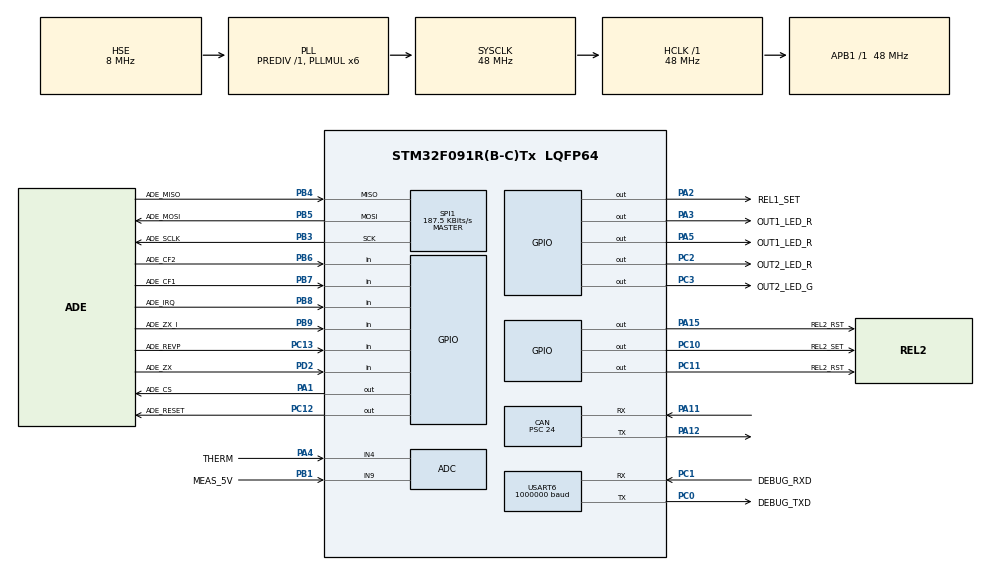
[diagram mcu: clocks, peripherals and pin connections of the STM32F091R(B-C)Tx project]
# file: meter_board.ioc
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CAN.BS1=CAN_BS1_13TQ
CAN.BS2=CAN_BS2_6TQ
CAN.CalculateTimeQuantum=500.0
CAN.Mode=CAN_MODE_LOOPBACK
CAN.Prescaler=24
FREERTOS.Tasks01=defaultTask,0,128,StartDefaultTask,Default,NULL
Mcu.Family=STM32F0
Mcu.Name=STM32F091R(B-C)Tx
Mcu.Package=LQFP64
NVIC.TIM1_BRK_UP_TRG_COM_IRQn=true\:0\:0\:false\:false\:true\:false\:false
NVIC.TimeBase=TIM1_BRK_UP_TRG_COM_IRQn
NVIC.TimeBaseIP=TIM1
PA1.GPIO_Label=ADE_CS
PA1.PinState=GPIO_PIN_SET
PA1.Signal=GPIO_Output
PA11.Mode=Master
PA11.Signal=CAN_RX
PA12.Mode=Master
PA12.Signal=CAN_TX
PA13.Mode=Serial_Wire
PA13.Signal=SYS_SWDIO
PA14.Mode=Serial_Wire
PA14.Signal=SYS_SWCLK
PA15.GPIO_Label=REL2_RST
PA15.Signal=GPIO_Output
PA2.GPIO_Label=REL1_SET
PA2.Signal=GPIO_Output
PA3.GPIO_Label=OUT1_LED_R
PA3.Signal=GPIO_Output
PA4.GPIO_Label=THERM
PA4.Mode=IN4
PA4.Signal=ADC_IN4
PA5.GPIO_Label=OUT1_LED_R
PA5.Signal=GPIO_Output
PB1.GPIO_Label=MEAS_5V
PB1.Mode=IN9
PB1.Signal=ADC_IN9
PB3.GPIO_Label=ADE_SCLK
PB3.Mode=Full_Duplex_Master
PB3.Signal=SPI1_SCK
PB4.GPIO_Label=ADE_MISO
PB4.Mode=Full_Duplex_Master
PB4.Signal=SPI1_MISO
PB5.GPIO_Label=ADE_MOSI
PB5.Mode=Full_Duplex_Master
PB5.Signal=SPI1_MOSI
PB6.GPIO_Label=ADE_CF2
PB6.Signal=GPIO_Input
PB7.GPIO_Label=ADE_CF1
PB7.Signal=GPIO_Input
PB8.GPIO_Label=ADE_IRQ
PB8.Signal=GPIO_Input
PB9.GPIO_Label=ADE_ZX_I
PB9.Signal=GPIO_Input
PC0.GPIO_Label=DEBUG_TXD
PC0.Mode=Asynchronous
PC0.Signal=USART6_TX
PC1.GPIO_Label=DEBUG_RXD
PC1.Mode=Asynchronous
PC1.Signal=USART6_RX
PC10.GPIO_Label=REL2_SET
PC10.Signal=GPIO_Output
PC11.GPIO_Label=REL2_RST
PC11.Signal=GPIO_Output
PC12.GPIO_Label=ADE_RESET
PC12.PinState=GPIO_PIN_SET
PC12.Signal=GPIO_Output
PC13.GPIO_Label=ADE_REVP
PC13.Signal=GPIO_Input
PC14OSC32_IN.GPIO_Label=CAN_LED_G
PC14OSC32_IN.Signal=GPIO_Output
PC15OSC32_OUT.GPIO_Label=CAN_LED_R
PC15OSC32_OUT.Signal=GPIO_Output
PC2.GPIO_Label=OUT2_LED_R
PC2.Signal=GPIO_Output
PC3.GPIO_Label=OUT2_LED_G
PC3.Signal=GPIO_Output
PD2.GPIO_Label=ADE_ZX
PD2.Signal=GPIO_Input
PF0-OSC_IN.Mode=HSE-External-Oscillator
PF0-OSC_IN.Signal=RCC_OSC_IN
PF1-OSC_OUT.Mode=HSE-External-Oscillator
PF1-OSC_OUT.Signal=RCC_OSC_OUT
ProjectManager.HeapSize=0x200
ProjectManager.StackSize=0x400
ProjectManager.TargetToolchain=SW4STM32
RCC.AHBFreq_Value=48000000
RCC.APB1Freq_Value=48000000
RCC.APB1TimFreq_Value=48000000
RCC.HCLKFreq_Value=48000000
RCC.PLLMUL=RCC_PLL_MUL6
RCC.PLLSourceVirtual=RCC_PLLSOURCE_HSE
RCC.SYSCLKFreq_VALUE=48000000
RCC.SYSCLKSource=RCC_SYSCLKSOURCE_PLLCLK
SPI1.BaudRatePrescaler=SPI_BAUDRATEPRESCALER_256
SPI1.CLKPhase=SPI_PHASE_2EDGE
SPI1.CLKPolarity=SPI_POLARITY_HIGH
SPI1.CalculateBaudRate=187.5 KBits/s
SPI1.DataSize=SPI_DATASIZE_8BIT
SPI1.Direction=SPI_DIRECTION_2LINES
SPI1.Mode=SPI_MODE_MASTER
SPI1.VirtualType=VM_MASTER
USART6.BaudRate=1000000
USART6.VirtualMode=VM_ASYNC
USART6.WordLength=WORDLENGTH_8B
VP_FREERTOS_VS_ENABLE.Mode=Enabled
VP_SYS_VS_tim1.Mode=TIM1
board=meter_board

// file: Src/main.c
/**
  ******************************************************************************
  * @file           : main.c
  * @brief          : Main program body
  ******************************************************************************
  * This notice applies to any and all portions of this file
  * that are not between comment pairs USER CODE BEGIN and
  * USER CODE END. Other portions of this file, whether
  * inserted by the user or by software development tools
  * are owned by their respective copyright owners.
  *
  * Copyright (c) 2018 STMicroelectronics International N.V.
  * All rights reserved.
  *
  * Redistribution and use in source and binary forms, with or without
  * modification, are permitted, provided that the following conditions are met:
  *
  * 1. Redistribution of source code must retain the above copyright notice,
  *    this list of conditions and the following disclaimer.
  * 2. Redistributions in binary form must reproduce the above copyright notice,
  *    this list of conditions and the following disclaimer in the documentation
  *    and/or other materials provided with the distribution.
  * 3. Neither the name of STMicroelectronics nor the names of other
  *    contributors to this software may be used to endorse or promote products
  *    derived from this software without specific written permission.
  * 4. This software, including modifications and/or derivative works of this
  *    software, must execute solely and exclusively on microcontroller or
  *    microprocessor devices manufactured by or for STMicroelectronics.
  * 5. Redistribution and use of this software other than as permitted under
  *    this license is void and will automatically terminate your rights under
  *    this license.
  *
  * THIS SOFTWARE IS PROVIDED BY STMICROELECTRONICS AND CONTRIBUTORS "AS IS"
  * AND ANY EXPRESS, IMPLIED OR STATUTORY WARRANTIES, INCLUDING, BUT NOT
  * LIMITED TO, THE IMPLIED WARRANTIES OF MERCHANTABILITY, FITNESS FOR A
  * PARTICULAR PURPOSE AND NON-INFRINGEMENT OF THIRD PARTY INTELLECTUAL PROPERTY
  * RIGHTS ARE DISCLAIMED TO THE FULLEST EXTENT PERMITTED BY LAW. IN NO EVENT
  * SHALL STMICROELECTRONICS OR CONTRIBUTORS BE LIABLE FOR ANY DIRECT, INDIRECT,
  * INCIDENTAL, SPECIAL, EXEMPLARY, OR CONSEQUENTIAL DAMAGES (INCLUDING, BUT NOT
  * LIMITED TO, PROCUREMENT OF SUBSTITUTE GOODS OR SERVICES; LOSS OF USE, DATA,
  * OR PROFITS; OR BUSINESS INTERRUPTION) HOWEVER CAUSED AND ON ANY THEORY OF
  * LIABILITY, WHETHER IN CONTRACT, STRICT LIABILITY, OR TORT (INCLUDING
  * NEGLIGENCE OR OTHERWISE) ARISING IN ANY WAY OUT OF THE USE OF THIS SOFTWARE,
  * EVEN IF ADVISED OF THE POSSIBILITY OF SUCH DAMAGE.
  *
  ******************************************************************************
  */
#include "main.h"
#include "stm32f0xx_hal.h"
#include "cmsis_os.h"
#include "adc.h"
#include "can.h"
#include "spi.h"
#include "usart.h"
#include "gpio.h"

/* USER CODE BEGIN PV */
/* Private variables ---------------------------------------------------------*/

/* USER CODE END PV */

void SystemClock_Config(void);
void MX_FREERTOS_Init(void);

/* USER CODE BEGIN PFP */
/* Private function prototypes -----------------------------------------------*/

/* USER CODE END PFP */

int main(void)
{

  /* MCU Configuration----------------------------------------------------------*/

  /* Reset of all peripherals, Initializes the Flash interface and the Systick. */
  HAL_Init();

  /* Configure the system clock */
  SystemClock_Config();

  /* Initialize all configured peripherals */
  MX_GPIO_Init();
  MX_USART6_UART_Init();
  MX_ADC_Init();
  MX_SPI1_Init();
  MX_CAN_Init();
  /* USER CODE BEGIN 2 */
  __HAL_DBGMCU_FREEZE_TIM1();

  /* USER CODE END 2 */

  /* Call init function for freertos objects (in freertos.c) */
  MX_FREERTOS_Init();

  /* Start scheduler */
  osKernelStart();

  /* We should never get here as control is now taken by the scheduler */

  /* Infinite loop */
	while (1) {

	}

}

void SystemClock_Config(void)
{

  RCC_OscInitTypeDef RCC_OscInitStruct;
  RCC_ClkInitTypeDef RCC_ClkInitStruct;

    /**Initializes the CPU, AHB and APB busses clocks
    */
  RCC_OscInitStruct.OscillatorType = RCC_OSCILLATORTYPE_HSI14|RCC_OSCILLATORTYPE_HSE;
  RCC_OscInitStruct.HSEState = RCC_HSE_ON;
  RCC_OscInitStruct.HSI14State = RCC_HSI14_ON;
  RCC_OscInitStruct.HSI14CalibrationValue = 16;
  RCC_OscInitStruct.PLL.PLLState = RCC_PLL_ON;
  RCC_OscInitStruct.PLL.PLLSource = RCC_PLLSOURCE_HSE;
  RCC_OscInitStruct.PLL.PLLMUL = RCC_PLL_MUL6;
  RCC_OscInitStruct.PLL.PREDIV = RCC_PREDIV_DIV1;
  if (HAL_RCC_OscConfig(&RCC_OscInitStruct) != HAL_OK)
  {
    _Error_Handler(__FILE__, __LINE__);
  }

    /**Initializes the CPU, AHB and APB busses clocks
    */
  RCC_ClkInitStruct.ClockType = RCC_CLOCKTYPE_HCLK|RCC_CLOCKTYPE_SYSCLK
                              |RCC_CLOCKTYPE_PCLK1;
  RCC_ClkInitStruct.SYSCLKSource = RCC_SYSCLKSOURCE_PLLCLK;
  RCC_ClkInitStruct.AHBCLKDivider = RCC_SYSCLK_DIV1;
  RCC_ClkInitStruct.APB1CLKDivider = RCC_HCLK_DIV1;

  if (HAL_RCC_ClockConfig(&RCC_ClkInitStruct, FLASH_LATENCY_1) != HAL_OK)
  {
    _Error_Handler(__FILE__, __LINE__);
  }

    /**Configure the Systick interrupt time
    */
  HAL_SYSTICK_Config(HAL_RCC_GetHCLKFreq()/1000);

    /**Configure the Systick
    */
  HAL_SYSTICK_CLKSourceConfig(SYSTICK_CLKSOURCE_HCLK);

  /* SysTick_IRQn interrupt configuration */
  HAL_NVIC_SetPriority(SysTick_IRQn, 3, 0);
}

void HAL_TIM_PeriodElapsedCallback(TIM_HandleTypeDef *htim)
{
  if (htim->Instance == TIM1) {
    HAL_IncTick();
  }
}

void _Error_Handler(char *file, int line)
{
	while (1) {
	}
}

/************************ (C) COPYRIGHT STMicroelectronics *****END OF FILE****/

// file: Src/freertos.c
/**
 ******************************************************************************
 * File Name          : freertos.c
 * Description        : Code for freertos applications
 ******************************************************************************
 * This notice applies to any and all portions of this file
 * that are not between comment pairs USER CODE BEGIN and
 * USER CODE END. Other portions of this file, whether
 * inserted by the user or by software development tools
 * are owned by their respective copyright owners.
 *
 * Copyright (c) 2018 STMicroelectronics International N.V.
 * All rights reserved.
 *
 * Redistribution and use in source and binary forms, with or without
 * modification, are permitted, provided that the following conditions are met:
 *
 * 1. Redistribution of source code must retain the above copyright notice,
 *    this list of conditions and the following disclaimer.
 * 2. Redistributions in binary form must reproduce the above copyright notice,
 *    this list of conditions and the following disclaimer in the documentation
 *    and/or other materials provided with the distribution.
 * 3. Neither the name of STMicroelectronics nor the names of other
 *    contributors to this software may be used to endorse or promote products
 *    derived from this software without specific written permission.
 * 4. This software, including modifications and/or derivative works of this
 *    software, must execute solely and exclusively on microcontroller or
 *    microprocessor devices manufactured by or for STMicroelectronics.
 * 5. Redistribution and use of this software other than as permitted under
 *    this license is void and will automatically terminate your rights under
 *    this license.
 *
 * THIS SOFTWARE IS PROVIDED BY STMICROELECTRONICS AND CONTRIBUTORS "AS IS"
 * AND ANY EXPRESS, IMPLIED OR STATUTORY WARRANTIES, INCLUDING, BUT NOT
 * LIMITED TO, THE IMPLIED WARRANTIES OF MERCHANTABILITY, FITNESS FOR A
 * PARTICULAR PURPOSE AND NON-INFRINGEMENT OF THIRD PARTY INTELLECTUAL PROPERTY
 * RIGHTS ARE DISCLAIMED TO THE FULLEST EXTENT PERMITTED BY LAW. IN NO EVENT
 * SHALL STMICROELECTRONICS OR CONTRIBUTORS BE LIABLE FOR ANY DIRECT, INDIRECT,
 * INCIDENTAL, SPECIAL, EXEMPLARY, OR CONSEQUENTIAL DAMAGES (INCLUDING, BUT NOT
 * LIMITED TO, PROCUREMENT OF SUBSTITUTE GOODS OR SERVICES; LOSS OF USE, DATA,
 * OR PROFITS; OR BUSINESS INTERRUPTION) HOWEVER CAUSED AND ON ANY THEORY OF
 * LIABILITY, WHETHER IN CONTRACT, STRICT LIABILITY, OR TORT (INCLUDING
 * NEGLIGENCE OR OTHERWISE) ARISING IN ANY WAY OUT OF THE USE OF THIS SOFTWARE,
 * EVEN IF ADVISED OF THE POSSIBILITY OF SUCH DAMAGE.
 *
 ******************************************************************************
 */

#include "FreeRTOS.h"
#include "task.h"
#include "cmsis_os.h"

/* USER CODE BEGIN Includes */

#include "ade.h"

/* USER CODE END Includes */

osThreadId defaultTaskHandle;

void StartDefaultTask(void const * argument);

void MX_FREERTOS_Init(void); /* (MISRA C 2004 rule 8.1) */

/* Hook prototypes */

/* Init FreeRTOS */

void MX_FREERTOS_Init(void)
{

	/* Create the thread(s) */
	/* definition and creation of defaultTask */
	osThreadDef(defaultTask, StartDefaultTask, osPriorityNormal, 0, 128);
	defaultTaskHandle = osThreadCreate(osThread(defaultTask), NULL);

	/* USER CODE BEGIN RTOS_THREADS */
	/* add threads, ... */

	xTaskCreate(vAdeTask, "AdeTask", 256, NULL, 1, NULL);

	/* USER CODE END RTOS_THREADS */

}

/* StartDefaultTask function */
void StartDefaultTask(void const * argument)
{

	/* USER CODE BEGIN StartDefaultTask */
	/* Infinite loop */
	for (;;)
	{
		osDelay(10);
	}
	/* USER CODE END StartDefaultTask */
}

/************************ (C) COPYRIGHT STMicroelectronics *****END OF FILE****/
